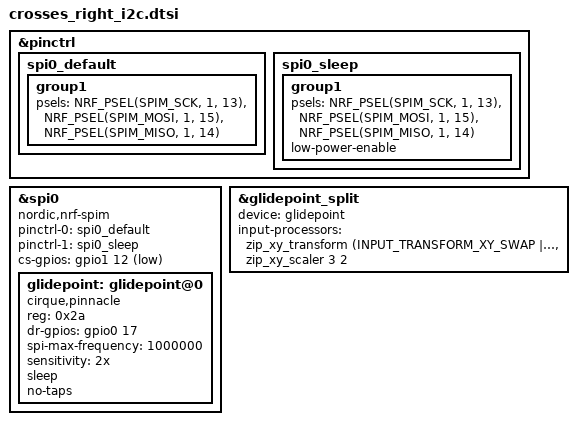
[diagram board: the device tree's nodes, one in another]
/*
 * Copyright (c) 2021 The ZMK Contributors
 *
 * SPDX-License-Identifier: MIT
 */

#include <input/processors.dtsi>
#include <dt-bindings/zmk/input_transform.h>
#include "crosses.dtsi"
#include <zephyr/input/input.h>

// Configure custom spi for the Right side

&pinctrl {
    spi0_default: spi0_default {
        group1 {
            psels = <NRF_PSEL(SPIM_SCK, 1, 13)>,
                <NRF_PSEL(SPIM_MOSI, 1, 15)>,
                <NRF_PSEL(SPIM_MISO, 1, 14)>;
        };
    };

    spi0_sleep: spi0_sleep {
        group1 {
            psels = <NRF_PSEL(SPIM_SCK, 1, 13)>,
                <NRF_PSEL(SPIM_MOSI, 1, 15)>,
                <NRF_PSEL(SPIM_MISO, 1, 14)>;
            low-power-enable;
        };
    };
};

&spi0 {
    status = "okay";
    compatible = "nordic,nrf-spim";
    pinctrl-0 = <&spi0_default>;
    pinctrl-1 = <&spi0_sleep>;
    pinctrl-names = "default", "sleep";
    cs-gpios = <&gpio1 12 GPIO_ACTIVE_LOW>;

    glidepoint: glidepoint@0 {
        compatible = "cirque,pinnacle";
        reg = <0x2a>;
        status = "okay";
        dr-gpios = <&gpio0 17 (GPIO_ACTIVE_HIGH)>;
        spi-max-frequency = <1000000>;
        sensitivity = "2x";
        sleep; 
        no-taps;
    };
};

&glidepoint_split {
	device = <&glidepoint>;
	input-processors = <&zip_xy_transform (INPUT_TRANSFORM_XY_SWAP | INPUT_TRANSFORM_X_INVERT | INPUT_TRANSFORM_Y_INVERT)>, <&zip_xy_scaler 3 2>;
};

// Cirque Trackpad

&glidepoint {
	status = "okay";
};
